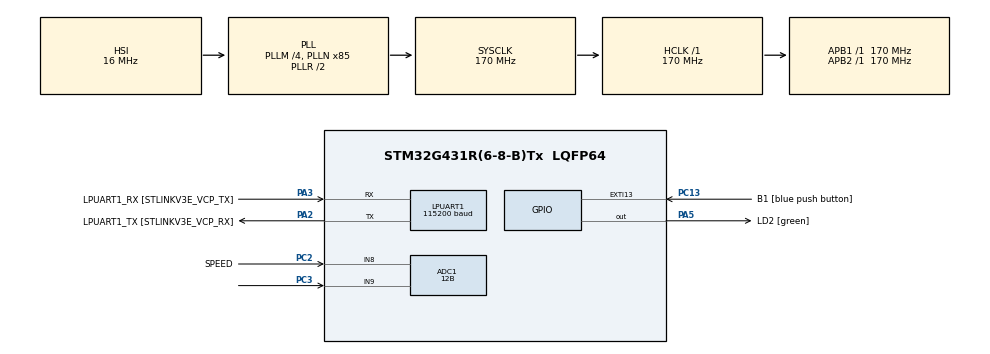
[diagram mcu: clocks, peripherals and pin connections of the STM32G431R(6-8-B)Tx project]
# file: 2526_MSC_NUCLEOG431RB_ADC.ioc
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ADC1.Channel-0\#ChannelRegularConversion=ADC_CHANNEL_8
ADC1.Channel-1\#ChannelRegularConversion=ADC_CHANNEL_9
ADC1.DMAContinuousRequests=ENABLE
ADC1.ExternalTrigConv=ADC_EXTERNALTRIG_T1_TRGO
ADC1.NbrOfConversion=2
ADC1.NbrOfConversionFlag=1
ADC1.OffsetNumber-0\#ChannelRegularConversion=ADC_OFFSET_NONE
ADC1.OffsetNumber-1\#ChannelRegularConversion=ADC_OFFSET_NONE
ADC1.Rank-0\#ChannelRegularConversion=1
ADC1.Rank-1\#ChannelRegularConversion=2
ADC1.Resolution=ADC_RESOLUTION_12B
ADC1.SamplingTime-0\#ChannelRegularConversion=ADC_SAMPLETIME_47CYCLES_5
ADC1.SamplingTime-1\#ChannelRegularConversion=ADC_SAMPLETIME_47CYCLES_5
ADC1.master=1
Dma.ADC1.0.Direction=DMA_PERIPH_TO_MEMORY
Dma.ADC1.0.EventEnable=DISABLE
Dma.ADC1.0.Instance=DMA1_Channel1
Dma.ADC1.0.MemDataAlignment=DMA_MDATAALIGN_HALFWORD
Dma.ADC1.0.MemInc=DMA_MINC_ENABLE
Dma.ADC1.0.Mode=DMA_CIRCULAR
Dma.ADC1.0.PeriphDataAlignment=DMA_PDATAALIGN_HALFWORD
Dma.ADC1.0.PeriphInc=DMA_PINC_DISABLE
Dma.ADC1.0.Polarity=HAL_DMAMUX_REQ_GEN_RISING
Dma.ADC1.0.Priority=DMA_PRIORITY_LOW
Dma.ADC1.0.RequestNumber=1
Dma.ADC1.0.SignalID=NONE
Dma.ADC1.0.SyncEnable=DISABLE
Dma.ADC1.0.SyncPolarity=HAL_DMAMUX_SYNC_NO_EVENT
Dma.ADC1.0.SyncRequestNumber=1
Dma.ADC1.0.SyncSignalID=NONE
Dma.Request0=ADC1
LPUART1.BaudRate=115200
Mcu.Family=STM32G4
Mcu.Name=STM32G431R(6-8-B)Tx
Mcu.Package=LQFP64
NVIC.DMA1_Channel1_IRQn=true\:0\:0\:false\:false\:true\:false\:true\:true
NVIC.PriorityGroup=NVIC_PRIORITYGROUP_4
PA13.GPIO_Label=T_SWDIO
PA13.Signal=SYS_JTMS-SWDIO
PA14.GPIO_Label=T_SWCLK
PA14.Signal=SYS_JTCK-SWCLK
PA2.GPIO_Label=LPUART1_TX [STLINKV3E_VCP_RX]
PA2.Mode=Asynchronous
PA2.Signal=LPUART1_TX
PA3.GPIO_Label=LPUART1_RX [STLINKV3E_VCP_TX]
PA3.Mode=Asynchronous
PA3.Signal=LPUART1_RX
PA5.GPIO_Label=LD2 [green]
PA5.Signal=GPIO_Output
PB3.GPIO_Label=T_SWO
PB3.Signal=SYS_JTDO-SWO
PC13.GPIO_Label=B1 [blue push button]
PC13.Signal=GPXTI13
PC14-OSC32_IN.GPIO_Label=RCC_OSC32_OUT
PC14-OSC32_IN.Signal=RCC_OSC32_IN
PC15-OSC32_OUT.GPIO_Label=RCC_OSC32_OUT
PC15-OSC32_OUT.Signal=RCC_OSC32_OUT
PC2.GPIO_Label=SPEED
PC2.Mode=IN8-Single-Ended
PC2.Signal=ADC1_IN8
PC3.Mode=IN9-Single-Ended
PC3.Signal=ADC1_IN9
PF0-OSC_IN.GPIO_Label=RCC_OSC_IN
PF0-OSC_IN.Signal=RCC_OSC_IN
PF1-OSC_OUT.GPIO_Label=RCC_OSC_OUT
PF1-OSC_OUT.Signal=RCC_OSC_OUT
ProjectManager.HeapSize=0x200
ProjectManager.StackSize=0x400
ProjectManager.TargetToolchain=STM32CubeIDE
RCC.ADC12Freq_Value=170000000
RCC.AHBFreq_Value=170000000
RCC.APB1Freq_Value=170000000
RCC.APB1TimFreq_Value=170000000
RCC.APB2Freq_Value=170000000
RCC.APB2TimFreq_Value=170000000
RCC.CortexFreq_Value=170000000
RCC.EXTERNAL_CLOCK_VALUE=12288000
RCC.HCLKFreq_Value=170000000
RCC.HSE_VALUE=24000000
RCC.HSI48_VALUE=48000000
RCC.HSI_VALUE=16000000
RCC.LSE_VALUE=32768
RCC.PLLM=RCC_PLLM_DIV4
RCC.PLLN=85
RCC.RTCClockSelection=RCC_RTCCLKSOURCE_LSE
RCC.SYSCLKFreq_VALUE=170000000
RCC.SYSCLKSource=RCC_SYSCLKSOURCE_PLLCLK
RCC.USBFreq_Value=170000000
RCC.VCOOutputFreq_Value=340000000
TIM1.PeriodNoDither=10000-1
TIM1.Prescaler=17000-1
TIM1.TIM_MasterOutputTrigger=TIM_TRGO_UPDATE
VP_SYS_VS_DBSignals.Mode=DisableDeadBatterySignals
VP_TIM1_VS_ClockSourceINT.Mode=Internal
board=NUCLEO-G431RB

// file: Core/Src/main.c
/* USER CODE BEGIN Header */
/**
 ******************************************************************************
 * @file           : main.c
 * @brief          : Main program body
 ******************************************************************************
 * @attention
 *
 * Copyright (c) 2025 STMicroelectronics.
 * All rights reserved.
 *
 * This software is licensed under terms that can be found in the LICENSE file
 * in the root directory of this software component.
 * If no LICENSE file comes with this software, it is provided AS-IS.
 *
 ******************************************************************************
 */
/* USER CODE END Header */
#include "main.h"
#include "adc.h"
#include "dma.h"
#include "usart.h"
#include "tim.h"
#include "gpio.h"

void SystemClock_Config(void);

/* USER CODE BEGIN 0 */
int __io_putchar(int ch)
{
	HAL_UART_Transmit(&hlpuart1, (uint8_t *)&ch, 1, HAL_MAX_DELAY);
	return ch;
}
/* USER CODE END 0 */

int main(void)
{

  /* USER CODE BEGIN 1 */
	uint16_t value[2];
  /* USER CODE END 1 */

  /* MCU Configuration--------------------------------------------------------*/

  /* Reset of all peripherals, Initializes the Flash interface and the Systick. */
  HAL_Init();

  /* Configure the system clock */
  SystemClock_Config();

  /* Initialize all configured peripherals */
  MX_GPIO_Init();
  MX_DMA_Init();
  MX_ADC1_Init();
  MX_LPUART1_UART_Init();
  MX_TIM1_Init();
  /* USER CODE BEGIN 2 */
	printf("Test ADC on Nucleoboard\r\n");
  /* USER CODE END 2 */

  /* Infinite loop */
  /* USER CODE BEGIN WHILE */
	HAL_ADCEx_Calibration_Start(&hadc1, ADC_SINGLE_ENDED);
	HAL_ADC_Start_DMA(&hadc1, value, 2);
	HAL_TIM_Base_Start(&htim1);
	while (1)
	{
//		HAL_ADC_Start(&hadc1);
//		HAL_ADC_PollForConversion(&hadc1, HAL_MAX_DELAY);
//		value = HAL_ADC_GetValue(&hadc1);
		printf("ADC value 0 : %4d\r\n", value[0]);
		printf("ADC value 1 : %4d\r\n", value[1]);
		HAL_Delay(1000);
    /* USER CODE END WHILE */

	}
}

void SystemClock_Config(void)
{
  RCC_OscInitTypeDef RCC_OscInitStruct = {0};
  RCC_ClkInitTypeDef RCC_ClkInitStruct = {0};

  /** Configure the main internal regulator output voltage
  */
  HAL_PWREx_ControlVoltageScaling(PWR_REGULATOR_VOLTAGE_SCALE1_BOOST);

  /** Initializes the RCC Oscillators according to the specified parameters
  * in the RCC_OscInitTypeDef structure.
  */
  RCC_OscInitStruct.OscillatorType = RCC_OSCILLATORTYPE_HSI;
  RCC_OscInitStruct.HSIState = RCC_HSI_ON;
  RCC_OscInitStruct.HSICalibrationValue = RCC_HSICALIBRATION_DEFAULT;
  RCC_OscInitStruct.PLL.PLLState = RCC_PLL_ON;
  RCC_OscInitStruct.PLL.PLLSource = RCC_PLLSOURCE_HSI;
  RCC_OscInitStruct.PLL.PLLM = RCC_PLLM_DIV4;
  RCC_OscInitStruct.PLL.PLLN = 85;
  RCC_OscInitStruct.PLL.PLLP = RCC_PLLP_DIV2;
  RCC_OscInitStruct.PLL.PLLQ = RCC_PLLQ_DIV2;
  RCC_OscInitStruct.PLL.PLLR = RCC_PLLR_DIV2;
  if (HAL_RCC_OscConfig(&RCC_OscInitStruct) != HAL_OK)
  {
    Error_Handler();
  }

  /** Initializes the CPU, AHB and APB buses clocks
  */
  RCC_ClkInitStruct.ClockType = RCC_CLOCKTYPE_HCLK|RCC_CLOCKTYPE_SYSCLK
                              |RCC_CLOCKTYPE_PCLK1|RCC_CLOCKTYPE_PCLK2;
  RCC_ClkInitStruct.SYSCLKSource = RCC_SYSCLKSOURCE_PLLCLK;
  RCC_ClkInitStruct.AHBCLKDivider = RCC_SYSCLK_DIV1;
  RCC_ClkInitStruct.APB1CLKDivider = RCC_HCLK_DIV1;
  RCC_ClkInitStruct.APB2CLKDivider = RCC_HCLK_DIV1;

  if (HAL_RCC_ClockConfig(&RCC_ClkInitStruct, FLASH_LATENCY_4) != HAL_OK)
  {
    Error_Handler();
  }
}

void Error_Handler(void)
{
	__disable_irq();
	while (1)
	{
	}
}
